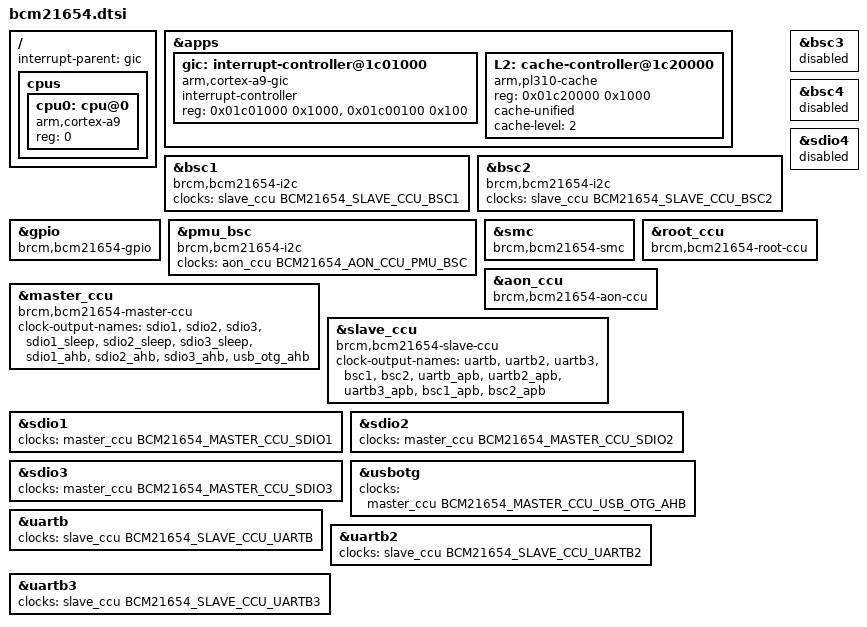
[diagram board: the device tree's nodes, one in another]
#include <dt-bindings/clock/bcm21654.h>
#include "bcm2166x-common.dtsi"

/ {
	interrupt-parent = <&gic>;

	cpus {
		#address-cells = <1>;
		#size-cells = <0>;

		cpu0: cpu@0 {
			device_type = "cpu";
			compatible = "arm,cortex-a9";
			reg = <0>;
		};
	};
};

&apps {
	gic: interrupt-controller@1c01000 {
		compatible = "arm,cortex-a9-gic";
		#interrupt-cells = <3>;
		#address-cells = <0>;
		interrupt-controller;
		reg = <0x01c01000 0x1000>,
		      <0x01c00100 0x100>;
	};

	L2: cache-controller@1c20000 {
		compatible = "arm,pl310-cache";
		reg = <0x01c20000 0x1000>;
		cache-unified;
		cache-level = <2>;
	};
};

&bsc1 {
	compatible = "brcm,bcm21654-i2c", "brcm,kona-i2c";
};

&bsc2 {
	compatible = "brcm,bcm21654-i2c", "brcm,kona-i2c";
};

/* BCM21654 only has BSC1 and BSC2, no BSC3/BSC4 */
&bsc3 {
	status = "disabled";
};

&bsc4 {
	status = "disabled";
};

&gpio {
	compatible = "brcm,bcm21654-gpio", "brcm,kona-gpio";
};

&pmu_bsc {
	compatible = "brcm,bcm21654-i2c", "brcm,kona-i2c";
};

&smc {
	compatible = "brcm,bcm21654-smc", "brcm,kona-smc";
};

/* BCM21654 only has 3 SDIO controllers, no SDIO4 */
&sdio4 {
	status = "disabled";
};

/* Override CCU nodes to use BCM21654-specific compatible strings and clocks */
&root_ccu {
	compatible = "brcm,bcm21654-root-ccu";
};

&aon_ccu {
	compatible = "brcm,bcm21654-aon-ccu";
};

&master_ccu {
	compatible = "brcm,bcm21654-master-ccu";
	clock-output-names = "sdio1",
			     "sdio2",
			     "sdio3",
			     "sdio1_sleep",
			     "sdio2_sleep",
			     "sdio3_sleep",
			     "sdio1_ahb",
			     "sdio2_ahb",
			     "sdio3_ahb",
			     "usb_otg_ahb";
};

&slave_ccu {
	compatible = "brcm,bcm21654-slave-ccu";
	clock-output-names = "uartb",
			     "uartb2",
			     "uartb3",
			     "bsc1",
			     "bsc2",
			     "uartb_apb",
			     "uartb2_apb",
			     "uartb3_apb",
			     "bsc1_apb",
			     "bsc2_apb";
};

/* Update clock references to use BCM21654 clock IDs */
&sdio1 {
	clocks = <&master_ccu BCM21654_MASTER_CCU_SDIO1>;
};

&sdio2 {
	clocks = <&master_ccu BCM21654_MASTER_CCU_SDIO2>;
};

&sdio3 {
	clocks = <&master_ccu BCM21654_MASTER_CCU_SDIO3>;
};

&usbotg {
	clocks = <&master_ccu BCM21654_MASTER_CCU_USB_OTG_AHB>;
};

&uartb {
	clocks = <&slave_ccu BCM21654_SLAVE_CCU_UARTB>;
};

&uartb2 {
	clocks = <&slave_ccu BCM21654_SLAVE_CCU_UARTB2>;
};

&uartb3 {
	clocks = <&slave_ccu BCM21654_SLAVE_CCU_UARTB3>;
};

&bsc1 {
	clocks = <&slave_ccu BCM21654_SLAVE_CCU_BSC1>;
};

&bsc2 {
	clocks = <&slave_ccu BCM21654_SLAVE_CCU_BSC2>;
};

&pmu_bsc {
	clocks = <&aon_ccu BCM21654_AON_CCU_PMU_BSC>;
};
